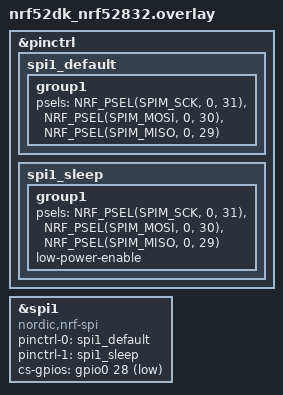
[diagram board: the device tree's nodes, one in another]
// To get started, press Ctrl+Space to bring up the completion menu and view the available nodes.

// You can also use the buttons in the sidebar to perform actions on nodes.
// Actions currently available include:

// * Enabling / disabling the node
// * Adding the bus to a bus
// * Removing the node
// * Connecting ADC channels

// For more help, browse the DeviceTree documentation at https://docs.zephyrproject.org/latest/guides/dts/index.html
// You can also visit the nRF DeviceTree extension documentation at https://nrfconnect.github.io/vscode-nrf-connect/devicetree/nrfdevicetree.html
&pinctrl {
	spi1_default: spi1_default {
		group1 {
			psels = <NRF_PSEL(SPIM_SCK, 0, 31)>,
					<NRF_PSEL(SPIM_MOSI, 0, 30)>,
					<NRF_PSEL(SPIM_MISO, 0, 29)>;
		};
	};

	spi1_sleep: spi1_sleep {
		group1 {
			psels = <NRF_PSEL(SPIM_SCK, 0, 31)>,
					<NRF_PSEL(SPIM_MOSI, 0, 30)>,
					<NRF_PSEL(SPIM_MISO, 0, 29)>;
			low-power-enable;
		};
	};
};

&spi1 {
	compatible = "nordic,nrf-spi";
	status = "okay";
	pinctrl-0 = <&spi1_default>;
	pinctrl-1 = <&spi1_sleep>;
	cs-gpios = <&gpio0 28 GPIO_ACTIVE_LOW>;
};

